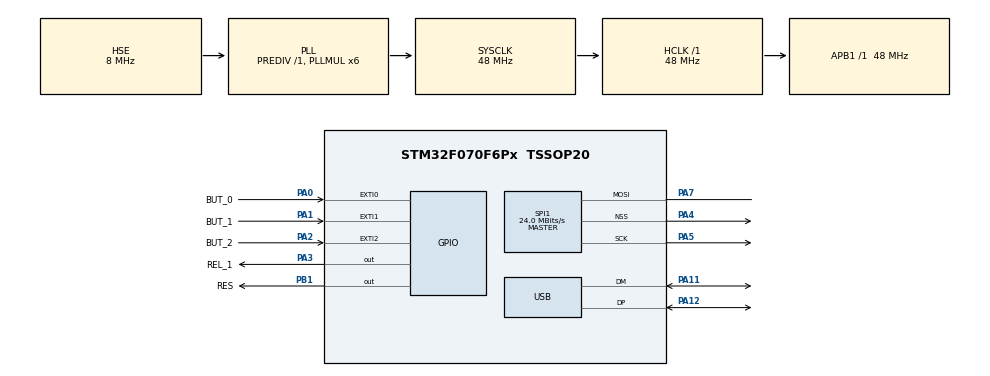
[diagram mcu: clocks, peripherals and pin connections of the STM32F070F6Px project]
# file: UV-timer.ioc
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Mcu.Family=STM32F0
Mcu.Name=STM32F070F6Px
Mcu.Package=TSSOP20
NVIC.EXTI0_1_IRQn=true\:0\:0\:false\:true\:true\:1\:true
NVIC.EXTI2_3_IRQn=true\:0\:0\:false\:true\:true\:2\:true
NVIC.USB_IRQn=true\:0\:0\:false\:false\:true\:false
PA0.GPIO_Label=BUT_0
PA0.GPIO_ModeDefaultEXTI=GPIO_MODE_IT_RISING
PA0.GPIO_PuPd=GPIO_PULLUP
PA0.Signal=GPXTI0
PA1.GPIO_Label=BUT_1
PA1.GPIO_PuPd=GPIO_PULLUP
PA1.Signal=GPXTI1
PA11.Mode=Device
PA11.Signal=USB_DM
PA12.Mode=Device
PA12.Signal=USB_DP
PA13.Mode=Serial_Wire
PA13.Signal=SYS_SWDIO
PA14.Mode=Serial_Wire
PA14.Signal=SYS_SWCLK
PA2.GPIO_Label=BUT_2
PA2.GPIO_PuPd=GPIO_PULLUP
PA2.Signal=GPXTI2
PA3.GPIO_Label=REL_1
PA3.Signal=GPIO_Output
PA4.Mode=NSS_Signal_Hard_Output
PA4.Signal=SPI1_NSS
PA5.Mode=Simplex_Bidirectional_Master
PA5.Signal=SPI1_SCK
PA7.Mode=Simplex_Bidirectional_Master
PA7.Signal=SPI1_MOSI
PB1.GPIO_Label=RES
PB1.Signal=GPIO_Output
PF0-OSC_IN.Mode=HSE-External-Oscillator
PF0-OSC_IN.Signal=RCC_OSC_IN
PF1-OSC_OUT.Mode=HSE-External-Oscillator
PF1-OSC_OUT.Signal=RCC_OSC_OUT
ProjectManager.HeapSize=0x200
ProjectManager.StackSize=0x400
ProjectManager.TargetToolchain=Makefile
RCC.AHBFreq_Value=48000000
RCC.APB1Freq_Value=48000000
RCC.APB1TimFreq_Value=48000000
RCC.HCLKFreq_Value=48000000
RCC.PLLMUL=RCC_PLL_MUL6
RCC.SYSCLKFreq_VALUE=48000000
RCC.SYSCLKSource=RCC_SYSCLKSOURCE_PLLCLK
SPI1.BaudRatePrescaler=SPI_BAUDRATEPRESCALER_2
SPI1.CalculateBaudRate=24.0 MBits/s
SPI1.Direction=SPI_DIRECTION_1LINE
SPI1.Mode=SPI_MODE_MASTER
SPI1.VirtualNSS=VM_NSSHARD
SPI1.VirtualType=VM_MASTER
USB_DEVICE.CLASS_NAME_FS=DFU
USB_DEVICE.VirtualMode=Dfu
USB_DEVICE.VirtualModeFS=Dfu_FS
VP_SYS_VS_PINREMAP.Mode=PINREMAP
VP_USB_DEVICE_VS_USB_DEVICE_DFU_FS.Mode=DFU_FS
board=UV-timer

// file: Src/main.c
/**
  ******************************************************************************
  * @file           : main.c
  * @brief          : Main program body
  ******************************************************************************
  * This notice applies to any and all portions of this file
  * that are not between comment pairs USER CODE BEGIN and
  * USER CODE END. Other portions of this file, whether
  * inserted by the user or by software development tools
  * are owned by their respective copyright owners.
  *
  * Copyright (c) 2018 STMicroelectronics International N.V.
  * All rights reserved.
  *
  * Redistribution and use in source and binary forms, with or without
  * modification, are permitted, provided that the following conditions are met:
  *
  * 1. Redistribution of source code must retain the above copyright notice,
  *    this list of conditions and the following disclaimer.
  * 2. Redistributions in binary form must reproduce the above copyright notice,
  *    this list of conditions and the following disclaimer in the documentation
  *    and/or other materials provided with the distribution.
  * 3. Neither the name of STMicroelectronics nor the names of other
  *    contributors to this software may be used to endorse or promote products
  *    derived from this software without specific written permission.
  * 4. This software, including modifications and/or derivative works of this
  *    software, must execute solely and exclusively on microcontroller or
  *    microprocessor devices manufactured by or for STMicroelectronics.
  * 5. Redistribution and use of this software other than as permitted under
  *    this license is void and will automatically terminate your rights under
  *    this license.
  *
  * THIS SOFTWARE IS PROVIDED BY STMICROELECTRONICS AND CONTRIBUTORS "AS IS"
  * AND ANY EXPRESS, IMPLIED OR STATUTORY WARRANTIES, INCLUDING, BUT NOT
  * LIMITED TO, THE IMPLIED WARRANTIES OF MERCHANTABILITY, FITNESS FOR A
  * PARTICULAR PURPOSE AND NON-INFRINGEMENT OF THIRD PARTY INTELLECTUAL PROPERTY
  * RIGHTS ARE DISCLAIMED TO THE FULLEST EXTENT PERMITTED BY LAW. IN NO EVENT
  * SHALL STMICROELECTRONICS OR CONTRIBUTORS BE LIABLE FOR ANY DIRECT, INDIRECT,
  * INCIDENTAL, SPECIAL, EXEMPLARY, OR CONSEQUENTIAL DAMAGES (INCLUDING, BUT NOT
  * LIMITED TO, PROCUREMENT OF SUBSTITUTE GOODS OR SERVICES; LOSS OF USE, DATA,
  * OR PROFITS; OR BUSINESS INTERRUPTION) HOWEVER CAUSED AND ON ANY THEORY OF
  * LIABILITY, WHETHER IN CONTRACT, STRICT LIABILITY, OR TORT (INCLUDING
  * NEGLIGENCE OR OTHERWISE) ARISING IN ANY WAY OUT OF THE USE OF THIS SOFTWARE,
  * EVEN IF ADVISED OF THE POSSIBILITY OF SUCH DAMAGE.
  *
  ******************************************************************************
  */
#include "main.h"
#include "stm32f0xx_hal.h"
#include "usb_device.h"

/* USER CODE BEGIN Includes */
#include "oled.h"
/* USER CODE END Includes */

SPI_HandleTypeDef hspi1;

/* USER CODE BEGIN PV */
/* Private variables ---------------------------------------------------------*/
/* USER CODE END PV */

void SystemClock_Config(void);
static void MX_GPIO_Init(void);
static void MX_SPI1_Init(void);
static void MX_NVIC_Init(void);

/* USER CODE BEGIN PFP */
/* Private function prototypes -----------------------------------------------*/
void wait_for_input();
void turn_on_lights();
void turn_off_lights();
/* USER CODE END PFP */

/* USER CODE BEGIN 0 */
char buffer[10];
int timer_seconds;
volatile int b0, b1, b2 = 0;
/* USER CODE END 0 */

int main(void)
{

  /* MCU Configuration----------------------------------------------------------*/

  /* Reset of all peripherals, Initializes the Flash interface and the Systick. */
  HAL_Init();

  /* Configure the system clock */
  SystemClock_Config();

  /* Initialize all configured peripherals */
  MX_GPIO_Init();
  MX_USB_DEVICE_Init();
  MX_SPI1_Init();

  /* Initialize interrupts */
  MX_NVIC_Init();
  /* USER CODE BEGIN 2 */

  oled_init();
  timer_seconds = 5*60; // 5 minutes

  turn_off_lights();

  oled_clear();
  oled_draw(10, 5, "OMG, a PCB :D");

  oled_show_buffer();
  HAL_Delay(1000);

  /* USER CODE END 2 */

  /* Infinite loop */
  while (1)
  {

  /* USER CODE BEGIN 3 */
    oled_clear();
    oled_draw_string(10, 5, "Press to start", 14, dialog);
    char buf[20];
    oled_seconds_to_minutes(timer_seconds, buf, 20);
    oled_draw_string(10, 5+16, buf, 11, dialog);
    oled_show_buffer();
    wait_for_input();
    turn_on_lights();
    //timer_seconds = 5*60; // 5 minutes
    while(1){
        oled_clear();
        char buf[20];
        oled_draw_string(10, 5, "Time remaining", 14, dialog);
        oled_seconds_to_minutes(timer_seconds, buf, 20);
        oled_draw_string(10, 5+16, buf, 11, dialog);
        oled_show_buffer();
        timer_seconds--;
        HAL_Delay(1000);
        if(timer_seconds == 0){
            turn_off_lights();
            timer_seconds = 5*60; // 5 minutes
            break;
        }
    }
  }
  /* USER CODE END 3 */

}

void SystemClock_Config(void)
{

  RCC_OscInitTypeDef RCC_OscInitStruct;
  RCC_ClkInitTypeDef RCC_ClkInitStruct;
  RCC_PeriphCLKInitTypeDef PeriphClkInit;

    /**Initializes the CPU, AHB and APB busses clocks
    */
  RCC_OscInitStruct.OscillatorType = RCC_OSCILLATORTYPE_HSE;
  RCC_OscInitStruct.HSEState = RCC_HSE_ON;
  RCC_OscInitStruct.PLL.PLLState = RCC_PLL_ON;
  RCC_OscInitStruct.PLL.PLLSource = RCC_PLLSOURCE_HSE;
  RCC_OscInitStruct.PLL.PLLMUL = RCC_PLL_MUL6;
  RCC_OscInitStruct.PLL.PREDIV = RCC_PREDIV_DIV1;
  if (HAL_RCC_OscConfig(&RCC_OscInitStruct) != HAL_OK)
  {
    _Error_Handler(__FILE__, __LINE__);
  }

    /**Initializes the CPU, AHB and APB busses clocks
    */
  RCC_ClkInitStruct.ClockType = RCC_CLOCKTYPE_HCLK|RCC_CLOCKTYPE_SYSCLK
                              |RCC_CLOCKTYPE_PCLK1;
  RCC_ClkInitStruct.SYSCLKSource = RCC_SYSCLKSOURCE_PLLCLK;
  RCC_ClkInitStruct.AHBCLKDivider = RCC_SYSCLK_DIV1;
  RCC_ClkInitStruct.APB1CLKDivider = RCC_HCLK_DIV1;

  if (HAL_RCC_ClockConfig(&RCC_ClkInitStruct, FLASH_LATENCY_1) != HAL_OK)
  {
    _Error_Handler(__FILE__, __LINE__);
  }

  PeriphClkInit.PeriphClockSelection = RCC_PERIPHCLK_USB;
  PeriphClkInit.UsbClockSelection = RCC_USBCLKSOURCE_PLL;

  if (HAL_RCCEx_PeriphCLKConfig(&PeriphClkInit) != HAL_OK)
  {
    _Error_Handler(__FILE__, __LINE__);
  }

    /**Configure the Systick interrupt time
    */
  HAL_SYSTICK_Config(HAL_RCC_GetHCLKFreq()/1000);

    /**Configure the Systick
    */
  HAL_SYSTICK_CLKSourceConfig(SYSTICK_CLKSOURCE_HCLK);

  /* SysTick_IRQn interrupt configuration */
  HAL_NVIC_SetPriority(SysTick_IRQn, 0, 0);
}

/**
  * @brief NVIC Configuration.
  * @retval None
  */
static void MX_NVIC_Init(void)
{
  /* EXTI0_1_IRQn interrupt configuration */
  HAL_NVIC_SetPriority(EXTI0_1_IRQn, 0, 0);
  HAL_NVIC_EnableIRQ(EXTI0_1_IRQn);
  /* EXTI2_3_IRQn interrupt configuration */
  HAL_NVIC_SetPriority(EXTI2_3_IRQn, 0, 0);
  HAL_NVIC_EnableIRQ(EXTI2_3_IRQn);
}

/* SPI1 init function */
static void MX_SPI1_Init(void)
{

  /* SPI1 parameter configuration*/
  hspi1.Instance = SPI1;
  hspi1.Init.Mode = SPI_MODE_MASTER;
  hspi1.Init.Direction = SPI_DIRECTION_2LINES;
  hspi1.Init.DataSize = SPI_DATASIZE_9BIT;
  hspi1.Init.CLKPolarity = SPI_POLARITY_LOW;
  hspi1.Init.CLKPhase = SPI_PHASE_1EDGE;
  hspi1.Init.NSS = SPI_NSS_HARD_OUTPUT;
  hspi1.Init.BaudRatePrescaler = SPI_BAUDRATEPRESCALER_64;
  hspi1.Init.FirstBit = SPI_FIRSTBIT_MSB;
  hspi1.Init.TIMode = SPI_TIMODE_DISABLE;
  hspi1.Init.CRCCalculation = SPI_CRCCALCULATION_DISABLE;
  hspi1.Init.CRCPolynomial = 7;
  hspi1.Init.CRCLength = SPI_CRC_LENGTH_DATASIZE;
  hspi1.Init.NSSPMode = SPI_NSS_PULSE_ENABLE;
  if (HAL_SPI_Init(&hspi1) != HAL_OK)
  {
    _Error_Handler(__FILE__, __LINE__);
  }

}

/** Configure pins as
        * Analog
        * Input
        * Output
        * EVENT_OUT
        * EXTI
*/
static void MX_GPIO_Init(void)
{

  GPIO_InitTypeDef GPIO_InitStruct;

  /* GPIO Ports Clock Enable */
  __HAL_RCC_GPIOF_CLK_ENABLE();
  __HAL_RCC_GPIOA_CLK_ENABLE();
  __HAL_RCC_GPIOB_CLK_ENABLE();

  /*Configure GPIO pin Output Level */
  HAL_GPIO_WritePin(GPIOA, REL_1_Pin|OLED_DC_Pin, GPIO_PIN_RESET);

  /*Configure GPIO pin Output Level */
  HAL_GPIO_WritePin(RES_GPIO_Port, RES_Pin, GPIO_PIN_RESET);

  /*Configure GPIO pins : BUT_0_Pin BUT_1_Pin BUT_2_Pin */
  GPIO_InitStruct.Pin = BUT_0_Pin|BUT_1_Pin|BUT_2_Pin;
  GPIO_InitStruct.Mode = GPIO_MODE_IT_RISING;
  GPIO_InitStruct.Pull = GPIO_PULLUP;
  HAL_GPIO_Init(GPIOA, &GPIO_InitStruct);

  /*Configure GPIO pins : REL_1_Pin OLED_DC_Pin */
  GPIO_InitStruct.Pin = REL_1_Pin|OLED_DC_Pin;
  GPIO_InitStruct.Mode = GPIO_MODE_OUTPUT_PP;
  GPIO_InitStruct.Pull = GPIO_NOPULL;
  GPIO_InitStruct.Speed = GPIO_SPEED_FREQ_LOW;
  HAL_GPIO_Init(GPIOA, &GPIO_InitStruct);

  /*Configure GPIO pin : RES_Pin */
  GPIO_InitStruct.Pin = RES_Pin;
  GPIO_InitStruct.Mode = GPIO_MODE_OUTPUT_PP;
  GPIO_InitStruct.Pull = GPIO_NOPULL;
  GPIO_InitStruct.Speed = GPIO_SPEED_FREQ_LOW;
  HAL_GPIO_Init(RES_GPIO_Port, &GPIO_InitStruct);

}

/* USER CODE BEGIN 4 */

void wait_for_input(){
    int b0_now = b0;
    while(1){
        if(b0 > b0_now)
            return;
    }
}

void turn_on_lights(){
    HAL_GPIO_WritePin(GPIOA, REL_1_Pin, GPIO_PIN_RESET);
}

void turn_off_lights(){
    HAL_GPIO_WritePin(GPIOA, REL_1_Pin, GPIO_PIN_SET);

}

/**
  * @brief EXTI line detection callbacks
  * @param GPIO_Pin: Specifies the pins connected EXTI line
  * @retval None
  */
void HAL_GPIO_EXTI_Callback(uint16_t GPIO_Pin){
    if(GPIO_Pin == BUT_0_Pin){
        b0++;
    }
    else if(GPIO_Pin == BUT_1_Pin){
        if(HAL_GPIO_ReadPin(GPIOA, BUT_2_Pin)){
            timer_seconds -= 10;
        }
        else{
            timer_seconds += 10;
        }
        oled_clear();
        char buf[20];
        oled_draw_string(10, 5, "Press to start", 14, dialog);
        oled_seconds_to_minutes(timer_seconds, buf, 20);
        oled_draw_string(10, 5+16, buf, 11, dialog);
        oled_show_buffer();
    }
}

/* USER CODE END 4 */

void _Error_Handler(char *file, int line)
{
  while(1)
  {
  }
}

/************************ (C) COPYRIGHT STMicroelectronics *****END OF FILE****/
